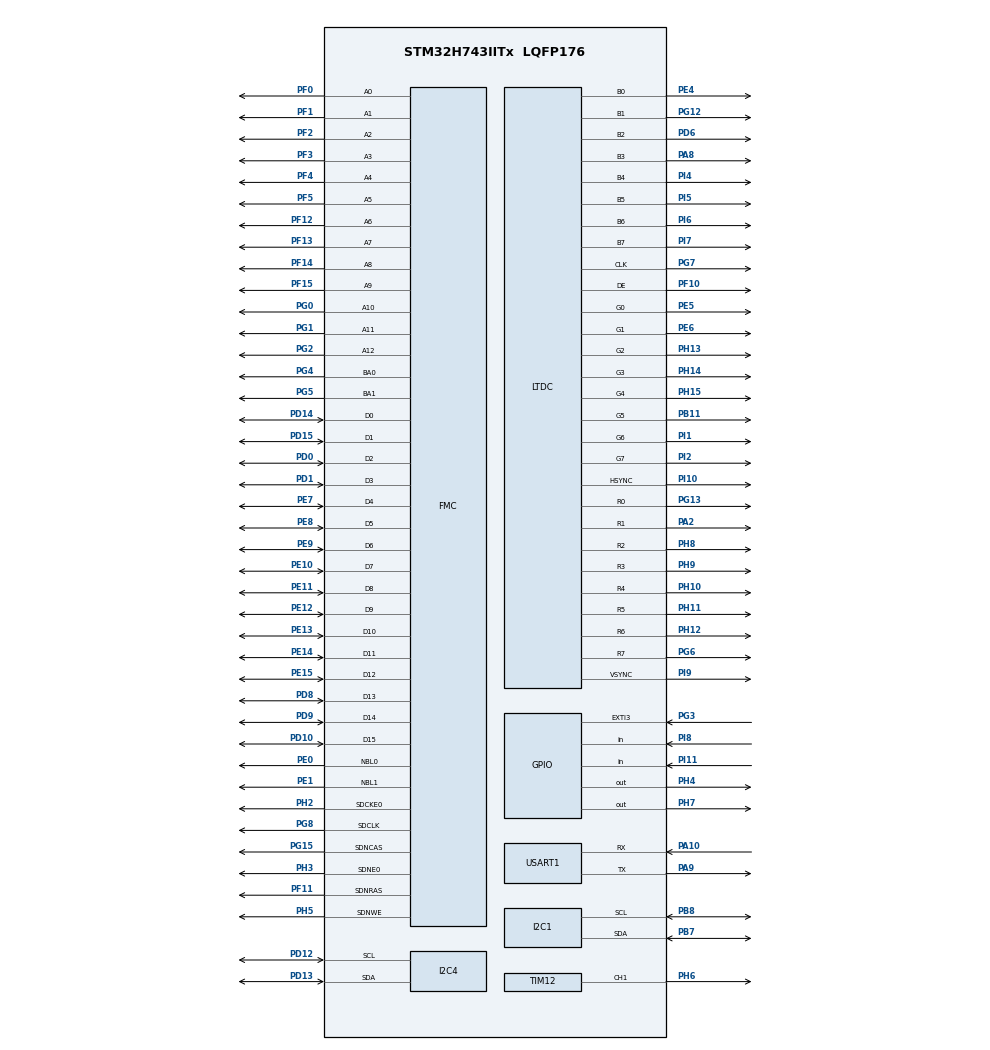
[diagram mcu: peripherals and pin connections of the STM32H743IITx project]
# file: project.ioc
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CORTEX_M7.default_mode_Activation=1
I2C1.Timing=0x00707CBB
I2C4.Timing=0x00707CBB
Mcu.Family=STM32H7
Mcu.Name=STM32H743IITx
Mcu.Package=LQFP176
NVIC.PriorityGroup=NVIC_PRIORITYGROUP_4
PA10.Mode=Asynchronous
PA10.Signal=USART1_RX
PA13\ (JTMS/SWDIO).Mode=JTAG_5_pins
PA13\ (JTMS/SWDIO).Signal=DEBUG_JTMS-SWDIO
PA14\ (JTCK/SWCLK).Mode=JTAG_5_pins
PA14\ (JTCK/SWCLK).Signal=DEBUG_JTCK-SWCLK
PA15\ (JTDI).Mode=JTAG_5_pins
PA15\ (JTDI).Signal=DEBUG_JTDI
PA2.Mode=RGB888
PA2.Signal=LTDC_R1
PA8.Mode=RGB888
PA8.Signal=LTDC_B3
PA9.Mode=Asynchronous
PA9.Signal=USART1_TX
PB11.Mode=RGB888
PB11.Signal=LTDC_G5
PB3\ (JTDO/TRACESWO).Mode=JTAG_5_pins
PB3\ (JTDO/TRACESWO).Signal=DEBUG_JTDO-SWO
PB4\ (NJTRST).Mode=JTAG_5_pins
PB4\ (NJTRST).Signal=DEBUG_JTRST
PB7.Mode=I2C
PB7.Signal=I2C1_SDA
PB8.Mode=I2C
PB8.Signal=I2C1_SCL
PD0.Signal=FMC_D2_DA2
PD1.Signal=FMC_D3_DA3
PD10.Signal=FMC_D15_DA15
PD12.Mode=I2C
PD12.Signal=I2C4_SCL
PD13.Mode=I2C
PD13.Signal=I2C4_SDA
PD14.Signal=FMC_D0_DA0
PD15.Signal=FMC_D1_DA1
PD6.Mode=RGB888
PD6.Signal=LTDC_B2
PD8.Signal=FMC_D13_DA13
PD9.Signal=FMC_D14_DA14
PE0.Signal=FMC_NBL0
PE1.Signal=FMC_NBL1
PE10.Signal=FMC_D7_DA7
PE11.Signal=FMC_D8_DA8
PE12.Signal=FMC_D9_DA9
PE13.Signal=FMC_D10_DA10
PE14.Signal=FMC_D11_DA11
PE15.Signal=FMC_D12_DA12
PE4.Mode=RGB888
PE4.Signal=LTDC_B0
PE5.Mode=RGB888
PE5.Signal=LTDC_G0
PE6.Mode=RGB888
PE6.Signal=LTDC_G1
PE7.Signal=FMC_D4_DA4
PE8.Signal=FMC_D5_DA5
PE9.Signal=FMC_D6_DA6
PF0.Signal=FMC_A0
PF1.Signal=FMC_A1
PF10.Mode=RGB888
PF10.Signal=LTDC_DE
PF11.Signal=FMC_SDNRAS
PF12.Signal=FMC_A6
PF13.Signal=FMC_A7
PF14.Signal=FMC_A8
PF15.Signal=FMC_A9
PF2.Signal=FMC_A2
PF3.Signal=FMC_A3
PF4.Signal=FMC_A4
PF5.Signal=FMC_A5
PG0.Signal=FMC_A10
PG1.Signal=FMC_A11
PG12.Mode=RGB888
PG12.Signal=LTDC_B1
PG13.Mode=RGB888
PG13.Signal=LTDC_R0
PG15.Signal=FMC_SDNCAS
PG2.Signal=FMC_A12
PG3.Signal=GPXTI3
PG4.Signal=FMC_A14_BA0
PG5.Signal=FMC_A15_BA1
PG6.Mode=RGB888
PG6.Signal=LTDC_R7
PG7.Mode=RGB888
PG7.Signal=LTDC_CLK
PG8.Signal=FMC_SDCLK
PH0-OSC_IN\ (PH0).Mode=HSE-External-Oscillator
PH0-OSC_IN\ (PH0).Signal=RCC_OSC_IN
PH1-OSC_OUT\ (PH1).Mode=HSE-External-Oscillator
PH1-OSC_OUT\ (PH1).Signal=RCC_OSC_OUT
PH10.Mode=RGB888
PH10.Signal=LTDC_R4
PH11.Mode=RGB888
PH11.Signal=LTDC_R5
PH12.Mode=RGB888
PH12.Signal=LTDC_R6
PH13.Mode=RGB888
PH13.Signal=LTDC_G2
PH14.Mode=RGB888
PH14.Signal=LTDC_G3
PH15.Mode=RGB888
PH15.Signal=LTDC_G4
PH2.Mode=SdramChipSelect1_1
PH2.Signal=FMC_SDCKE0
PH3.Mode=SdramChipSelect1_1
PH3.Signal=FMC_SDNE0
PH4.Signal=GPIO_Output
PH5.Signal=FMC_SDNWE
PH6.Signal=S_TIM12_CH1
PH7.Signal=GPIO_Output
PH8.Mode=RGB888
PH8.Signal=LTDC_R2
PH9.Mode=RGB888
PH9.Signal=LTDC_R3
PI1.Mode=RGB888
PI1.Signal=LTDC_G6
PI10.Mode=RGB888
PI10.Signal=LTDC_HSYNC
PI11.Signal=GPIO_Input
PI2.Mode=RGB888
PI2.Signal=LTDC_G7
PI4.Mode=RGB888
PI4.Signal=LTDC_B4
PI5.Mode=RGB888
PI5.Signal=LTDC_B5
PI6.Mode=RGB888
PI6.Signal=LTDC_B6
PI7.Mode=RGB888
PI7.Signal=LTDC_B7
PI8.Signal=GPIO_Input
PI9.Mode=RGB888
PI9.Signal=LTDC_VSYNC
ProjectManager.HeapSize=0x200
ProjectManager.StackSize=0x400
ProjectManager.TargetToolchain=Makefile
RCC.ADCFreq_Value=129000000
RCC.APB1Freq_Value=32000000
RCC.APB2Freq_Value=32000000
RCC.APB3Freq_Value=64000000
RCC.APB4Freq_Value=32000000
RCC.CortexFreq_Value=64000000
RCC.D2PPRE1=RCC_APB1_DIV2
RCC.D2PPRE2=RCC_APB2_DIV2
RCC.D3PPRE=RCC_APB4_DIV2
RCC.DIVM3=1
RCC.DIVN3=4
RCC.DIVR3=6
RCC.HCLKFreq_Value=64000000
RCC.PLL3FRACN=0
RCC.SYSCLKFreq_VALUE=64000000
RCC.USBFreq_Value=129000000
SH.FMC_A0.0=FMC_A0,13b-sda1
SH.FMC_A1.0=FMC_A1,13b-sda1
SH.FMC_A10.0=FMC_A10,13b-sda1
SH.FMC_A11.0=FMC_A11,13b-sda1
SH.FMC_A12.0=FMC_A12,13b-sda1
SH.FMC_A14_BA0.0=FMC_BA0,FourSdramBanks1
SH.FMC_A15_BA1.0=FMC_BA1,FourSdramBanks1
SH.FMC_A2.0=FMC_A2,13b-sda1
SH.FMC_A3.0=FMC_A3,13b-sda1
SH.FMC_A4.0=FMC_A4,13b-sda1
SH.FMC_A5.0=FMC_A5,13b-sda1
SH.FMC_A6.0=FMC_A6,13b-sda1
SH.FMC_A7.0=FMC_A7,13b-sda1
SH.FMC_A8.0=FMC_A8,13b-sda1
SH.FMC_A9.0=FMC_A9,13b-sda1
SH.FMC_D0_DA0.0=FMC_D0,sd-16b-d1
SH.FMC_D10_DA10.0=FMC_D10,sd-16b-d1
SH.FMC_D11_DA11.0=FMC_D11,sd-16b-d1
SH.FMC_D12_DA12.0=FMC_D12,sd-16b-d1
SH.FMC_D13_DA13.0=FMC_D13,sd-16b-d1
SH.FMC_D14_DA14.0=FMC_D14,sd-16b-d1
SH.FMC_D15_DA15.0=FMC_D15,sd-16b-d1
SH.FMC_D1_DA1.0=FMC_D1,sd-16b-d1
SH.FMC_D2_DA2.0=FMC_D2,sd-16b-d1
SH.FMC_D3_DA3.0=FMC_D3,sd-16b-d1
SH.FMC_D4_DA4.0=FMC_D4,sd-16b-d1
SH.FMC_D5_DA5.0=FMC_D5,sd-16b-d1
SH.FMC_D6_DA6.0=FMC_D6,sd-16b-d1
SH.FMC_D7_DA7.0=FMC_D7,sd-16b-d1
SH.FMC_D8_DA8.0=FMC_D8,sd-16b-d1
SH.FMC_D9_DA9.0=FMC_D9,sd-16b-d1
SH.FMC_NBL0.0=FMC_NBL0,Sd2ByteEnable1
SH.FMC_NBL1.0=FMC_NBL1,Sd2ByteEnable1
SH.FMC_SDCLK.0=FMC_SDCLK,13b-sda1
SH.FMC_SDNCAS.0=FMC_SDNCAS,13b-sda1
SH.FMC_SDNRAS.0=FMC_SDNRAS,13b-sda1
SH.FMC_SDNWE.0=FMC_SDNWE,13b-sda1
SH.S_TIM12_CH1.0=TIM12_CH1,PWM Generation1 CH1
TIM12.Channel-PWM\ Generation1\ CH1=TIM_CHANNEL_1
TIM12.Prescaler=84
TIM12.Pulse-PWM\ Generation1\ CH1=500
USART1.VirtualMode-Asynchronous=VM_ASYNC
VP_MEMORYMAP_VS_MEMORYMAP.Mode=CurAppReg
board=custom

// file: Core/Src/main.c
/* USER CODE BEGIN Header */
/**
 ******************************************************************************
 * @file           : main.c
 * @brief          : Main program body
 ******************************************************************************
 * @attention
 *
 * Copyright (c) 2025 STMicroelectronics.
 * All rights reserved.
 *
 * This software is licensed under terms that can be found in the LICENSE file
 * in the root directory of this software component.
 * If no LICENSE file comes with this software, it is provided AS-IS.
 *
 ******************************************************************************
 */
/* USER CODE END Header */
#include "main.h"
#include "fmc.h"
#include "gpio.h"
#include "i2c.h"
#include "ltdc.h"
#include "tim.h"
#include "usart.h"

void SystemClock_Config(void);
static void MPU_Config(void);

int main(void) {

  /* MPU Configuration--------------------------------------------------------*/
  MPU_Config();

  /* MCU Configuration--------------------------------------------------------*/

  /* Reset of all peripherals, Initializes the Flash interface and the Systick.
   */
  HAL_Init();

  /* Configure the system clock */
  SystemClock_Config();

  /* Initialize all configured peripherals */
  MX_GPIO_Init();
  MX_FMC_Init();
  MX_LTDC_Init();
  MX_I2C1_Init();
  MX_I2C4_Init();
  MX_USART1_UART_Init();
  MX_TIM12_Init();
  /* USER CODE BEGIN 2 */
  uint32_t *framebuffer = (uint32_t *)0xD0000000;

  for (int y = 0; y < 600; y++) {
    for (int x = 0; x < 1024; x++) {
      if (x < 256)
        framebuffer[y * 1024 + x] = 0xFFFF0000; // Red
      else if (x < 512)
        framebuffer[y * 1024 + x] = 0xFF00FF00; // Green
      else if (x < 768)
        framebuffer[y * 1024 + x] = 0xFF0000FF; // Blue
      else
        framebuffer[y * 1024 + x] = 0xFFFFFFFF; // White
    }
  }

  char *buf = "uart";
  HAL_TIM_PWM_Start(&htim12, TIM_CHANNEL_1);

  /* USER CODE END 2 */

  /* Infinite loop */
  while (1) {

    /* USER CODE BEGIN 3 */

    HAL_UART_Transmit(&huart1, buf, sizeof(buf), 20);
  }
  /* USER CODE END 3 */
}

void SystemClock_Config(void) {
  RCC_OscInitTypeDef RCC_OscInitStruct = {0};
  RCC_ClkInitTypeDef RCC_ClkInitStruct = {0};

  /** Supply configuration update enable
   */
  HAL_PWREx_ConfigSupply(PWR_LDO_SUPPLY);

  /** Configure the main internal regulator output voltage
   */
  __HAL_PWR_VOLTAGESCALING_CONFIG(PWR_REGULATOR_VOLTAGE_SCALE3);

  while (!__HAL_PWR_GET_FLAG(PWR_FLAG_VOSRDY)) {
  }

  /** Macro to configure the PLL clock source
   */
  __HAL_RCC_PLL_PLLSOURCE_CONFIG(RCC_PLLSOURCE_HSI);

  /** Initializes the RCC Oscillators according to the specified parameters
   * in the RCC_OscInitTypeDef structure.
   */
  RCC_OscInitStruct.OscillatorType = RCC_OSCILLATORTYPE_HSI;
  RCC_OscInitStruct.HSIState = RCC_HSI_DIV1;
  RCC_OscInitStruct.HSICalibrationValue = RCC_HSICALIBRATION_DEFAULT;
  RCC_OscInitStruct.PLL.PLLState = RCC_PLL_NONE;
  if (HAL_RCC_OscConfig(&RCC_OscInitStruct) != HAL_OK) {
    Error_Handler();
  }

  /** Initializes the CPU, AHB and APB buses clocks
   */
  RCC_ClkInitStruct.ClockType = RCC_CLOCKTYPE_HCLK | RCC_CLOCKTYPE_SYSCLK |
                                RCC_CLOCKTYPE_PCLK1 | RCC_CLOCKTYPE_PCLK2 |
                                RCC_CLOCKTYPE_D3PCLK1 | RCC_CLOCKTYPE_D1PCLK1;
  RCC_ClkInitStruct.SYSCLKSource = RCC_SYSCLKSOURCE_HSI;
  RCC_ClkInitStruct.SYSCLKDivider = RCC_SYSCLK_DIV1;
  RCC_ClkInitStruct.AHBCLKDivider = RCC_HCLK_DIV1;
  RCC_ClkInitStruct.APB3CLKDivider = RCC_APB3_DIV1;
  RCC_ClkInitStruct.APB1CLKDivider = RCC_APB1_DIV2;
  RCC_ClkInitStruct.APB2CLKDivider = RCC_APB2_DIV2;
  RCC_ClkInitStruct.APB4CLKDivider = RCC_APB4_DIV2;

  if (HAL_RCC_ClockConfig(&RCC_ClkInitStruct, FLASH_LATENCY_1) != HAL_OK) {
    Error_Handler();
  }
}

/* MPU Configuration */

void MPU_Config(void) {
  MPU_Region_InitTypeDef MPU_InitStruct = {0};

  /* Disables the MPU */
  HAL_MPU_Disable();

  /** Initializes and configures the Region and the memory to be protected
   */
  MPU_InitStruct.Enable = MPU_REGION_ENABLE;
  MPU_InitStruct.Number = MPU_REGION_NUMBER0;
  MPU_InitStruct.BaseAddress = 0x0;
  MPU_InitStruct.Size = MPU_REGION_SIZE_4GB;
  MPU_InitStruct.SubRegionDisable = 0x87;
  MPU_InitStruct.TypeExtField = MPU_TEX_LEVEL0;
  MPU_InitStruct.AccessPermission = MPU_REGION_NO_ACCESS;
  MPU_InitStruct.DisableExec = MPU_INSTRUCTION_ACCESS_DISABLE;
  MPU_InitStruct.IsShareable = MPU_ACCESS_SHAREABLE;
  MPU_InitStruct.IsCacheable = MPU_ACCESS_NOT_CACHEABLE;
  MPU_InitStruct.IsBufferable = MPU_ACCESS_NOT_BUFFERABLE;

  HAL_MPU_ConfigRegion(&MPU_InitStruct);
  /* Enables the MPU */
  HAL_MPU_Enable(MPU_PRIVILEGED_DEFAULT);
}

void Error_Handler(void) {
  __disable_irq();
  while (1) {
  }
}
#ifdef USE_FULL_ASSERT
/**
 * @brief  Reports the name of the source file and the source line number
 *         where the assert_param error has occurred.
 * @param  file: pointer to the source file name
 * @param  line: assert_param error line source number
 * @retval None
 */
void assert_failed(uint8_t *file, uint32_t line) {
  /* USER CODE BEGIN 6 */
  /* User can add his own implementation to report the file name and line
     number, ex: printf("Wrong parameters value: file %s on line %d\r\n", file,
     line) */
  /* USER CODE END 6 */
}
#endif /* USE_FULL_ASSERT */
